# GD32A72_A74x register map
File version: 1.0
CPU: CM7 r2p1, little endian, MPU, FPU, DSP, 4 interrupt priority bits
Registers are 32-bit, read-write, reset 0x0 unless marked. A register's access mark holds for its fields unless they carry their own. Offsets are from the block's base; [hi:lo] are bit positions.

## PMU — Power management unit
Base 0x40007000
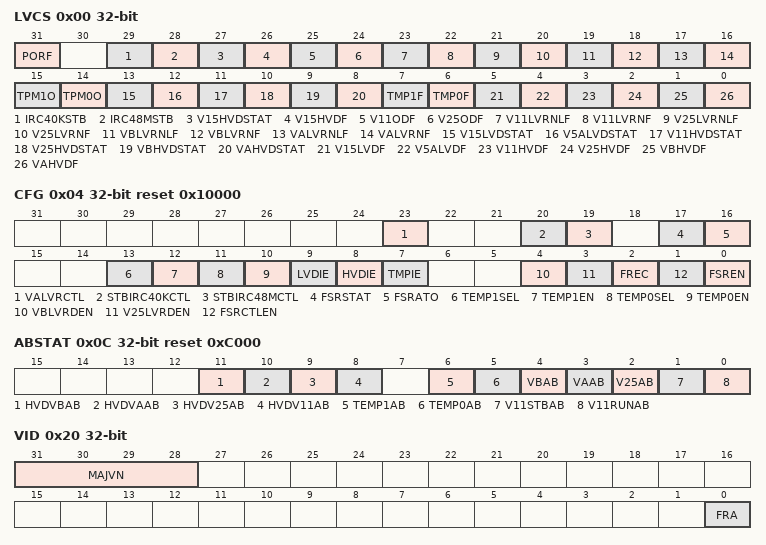
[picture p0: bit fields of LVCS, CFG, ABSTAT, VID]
0x00 LVCS access per field — Low voltage control and status register
  [31] PORF rw — POR flag
  [29] IRC40KSTB rw — irc40k stabilization status
  [28] IRC48MSTB rw — irc48m stabilization status
  [27] V15HVDSTAT ro — 1
  [26] V15HVDF rw — 1
  [25] V11ODF rw — Osc part of 1.1V domain detect flag
  [24] V25ODF rw — Osc part of 2.5V domain detect flag
  [23] V11LVRNLF rw — 1.1V domain Low voltage reset flag (NCM or LCM)
  [22] V11LVRNF rw — 1.1V domain Low voltage reset flag in NCM
  [21] V25LVRNLF rw — 2.5V domain Low voltage reset flag (NCM or LCM)
  [20] V25LVRNF rw — 2.5V domain Low voltage reset flag in NCM
  [19] VBLVRNLF rw — VDDB domain Low voltage reset flag (NCM or LCM)
  [18] VBLVRNF rw — VDDB domain Low voltage reset flag in NCM
  [17] VALVRNLF rw — VDDA domain Low voltage reset flag (NCM or LCM)
  [16] VALVRNF rw — VDDA domain Low voltage reset in NCM
  [15] TPM1O ro — Temperature monitor 1 output
  [14] TPM0O ro — Temperature monitor 0 output
  [13] V15LVDSTAT ro — 1.5V domain LVD status in NCM
  [12] V5ALVDSTAT ro — VDDA domain 5V LVD status in NCM
  [11] V11HVDSTAT ro — 1.1V domain HVD status on in NCM
  [10] V25HVDSTAT ro — 2.5V domain HVD status in NCM
  [9] VBHVDSTAT ro — VDDB domain HVD status on in NCM
  [8] VAHVDSTAT ro — VDDA domain HVD status on in NCM
  [7] TMP1F rw — Temperature monitor 1 interrupt flag for FMU
  [6] TMP0F rw — Temperature monitor 0 interrupt flag for FMU
  [5] V15LVDF rw — 1.5V domain LVD flag on in NCM
  [4] V5ALVDF rw — VDDA domain 5V LVD flag on in NCM
  [3] V11HVDF rw — 1.1V domain HVD flag on in NCM
  [2] V25HVDF rw — 2.5V domain HVD flag in NCM
  [1] VBHVDF rw — VDDB domain HVD flag in NCM
  [0] VAHVDF rw — VDDA domain HVD flag in NCM
0x04 CFG reset 0x10000 — Configuration register
  [23] VALVRCTL — control vdda lvr
  [20] STBIRC40KCTL — control whether irc40k is on in standby mode
  [19] STBIRC48MCTL — control whether irc48m is on in standby mode
  [17] FSRSTAT — Final step regulator status bit
  [16] FSRATO — Final step regulator auto turns over bit
  [13] TEMP1SEL — High temperature monitoring level selection
  [12] TEMP1EN — TEMP_M1 enable
  [11] TEMP0SEL — High temperature monitoring level selection
  [10] TEMP0EN — TEMP_M0 enable
  [9] LVDIE — Low voltage detects interrupt enable
  [8] HVDIE — High voltage detect interrupt enable
  [7] TMPIE — Temperature detect interrupt enable for FMU
  [4] VBLVRDEN — VDDB LVR detection enable bit during LCM
  [3] V25LVRDEN — 2.5V domain LVR detection enable bit during LCM
  [2] FREC — Fast recovery from LPM enable bit
  [1] FSRCTLEN — Final step regulator base control enable bit
  [0] FSREN — Final step regulator enable
0x08 ABCTL — Analog BIST control register
  [0] ABEN — Analog BIST enable signal
0x0C ABSTAT reset 0xC000 — Analog BIST status register
  [11] HVDVBAB — HVD VDDB ABIST test flag
  [10] HVDVAAB — HVD VDDA ABIST test flag
  [9] HVDV25AB — HVD V25 ABIST test flag
  [8] HVDV11AB — HVD V11 ABIST test flag
  [6] TEMP1AB — High temperature 1 ABIST
  [5] TEMP0AB — High temperature 0 ABIST
  [4] VBAB — vddb abist test status
  [3] VAAB — vdda abist test status
  [2] V25AB — 2.5V BIST test status
  [1] V11STBAB — 1.1V Standby ABIST test status
  [0] V11RUNAB — 1.1V RUN ABIST test status
0x20 VID ro — Version ID register
  [31:28] MAJVN — Major version number
  [0] FRA — Final step Regulator availability
0x24 CTLKEY — Control key register
  [15:0] CTLKEY — Control key
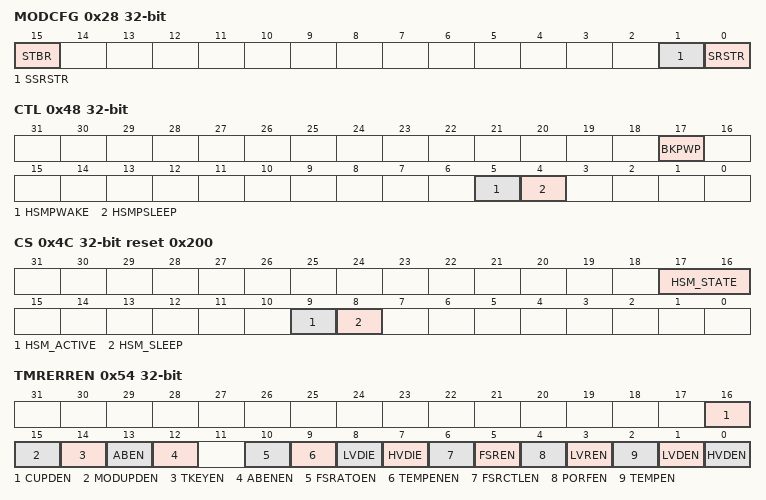
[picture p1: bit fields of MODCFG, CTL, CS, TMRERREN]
0x28 MODCFG — Mode configure register
  [15] STBR — Standby request
  [1] SSRSTR — Subsystem reset request
  [0] SRSTR — System reset request
0x2C MODUPD — Mode update register
  [0] MODUPD — Mode update
0x30 MODSTAT ro — Mode status register
  [1:0] PREMOD — Previous mode
0x34 C0BTADDR reset 0x24000000 — Core0 boot address register
  [31:0] C0BTADDR — core0 boot address
0x38 C1BTADDR reset 0x8000000 — Core1 boot address register
  [31:0] C1BTADDR — core1 boot address
0x3C MCID reset 0x8000000 — Main core ID register
  [0] MCID — main core id
0x40 CUPD — Core update register
  [0] CUPD — core update
0x48 CTL — Control register
  [17] BKPWP — Write protection for backup domain
  [5] HSMPWAKE — hsm power domain wakeup
  [4] HSMPSLEEP — hsm power domain go to power-off
0x4C CS ro reset 0x200 — Control and status register
  [17:16] HSM_STATE — HSM power state
  [9] HSM_ACTIVE — HSM power domain is in active state
  [8] HSM_SLEEP — hsm power domain is in sleep state
0x54 TMRERREN — TMR error enable register
  [16] CUPDEN — core update tmr error interrupt enable
  [15] MODUPDEN — mode update tmr error interrupt enable
  [14] TKEYEN — test key tmr error interrupt enable
  [13] ABEN — abist tmr error interrupt enable
  [12] ABENEN — abist enable interrupt enable
  [10] FSRATOEN — fsrato interrupt enable
  [9] TEMPENEN — temperature enable interrupt enable
  [8] LVDIE — lvd interrupt enable
  [7] HVDIE — hvd interrupt enable
  [6] FSRCTLEN — fsrctl interrupt enable
  [5] FSREN — fsr interrupt enable
  [4] PORFEN — porf tmr error interrupt enable
  [3] LVREN — lvr tmr error interrupt enable
  [2] TEMPEN — temperature interrupt enable
  [1] LVDEN — lvd tmr error interrupt enable
  [0] HVDEN — hvd tmr error interrupt enable
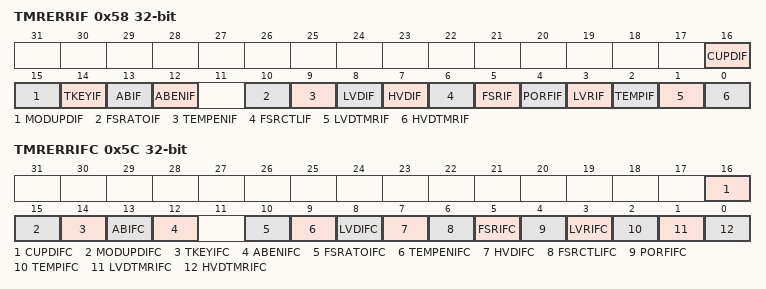
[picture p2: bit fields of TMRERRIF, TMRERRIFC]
0x58 TMRERRIF — TMR error interrupt register
  [16] CUPDIF — core update tmr error interrupt flag
  [15] MODUPDIF — mode update tmr error interrupt flag
  [14] TKEYIF — test key tmr error interrupt flag
  [13] ABIF — abist tmr error interrupt flag
  [12] ABENIF — abist enable interrupt flag
  [10] FSRATOIF — fsrato interrupt flag
  [9] TEMPENIF — temperature enable interrupt flag
  [8] LVDIF — lvd interrupt flag
  [7] HVDIF — hvd interrupt flag
  [6] FSRCTLIF — fsrctl interrupt flag
  [5] FSRIF — fsr interrupt flag
  [4] PORFIF — porf tmr error interrupt flag
  [3] LVRIF — lvr tmr error interrupt flag
  [2] TEMPIF — temperature interrupt flag
  [1] LVDTMRIF — lvd tmr error interrupt flag
  [0] HVDTMRIF — hvd tmr error interrupt flag
0x5C TMRERRIFC — TMR error interrupt clear register
  [16] CUPDIFC — core update tmr error interrupt flag clear
  [15] MODUPDIFC — mode update tmr error interrupt flag clear
  [14] TKEYIFC — test key tmr error interrupt flag clear
  [13] ABIFC — abist tmr error interrupt flag clear
  [12] ABENIFC — abist enable interrupt flag clear
  [10] FSRATOIFC — fsrato interrupt flag clear
  [9] TEMPENIFC — temperature enable interrupt flag clear
  [8] LVDIFC — lvd interrupt flag clear
  [7] HVDIFC — hvd interrupt flag clear
  [6] FSRCTLIFC — fsrctl interrupt flag clear
  [5] FSRIFC — fsr interrupt flag clear
  [4] PORFIFC — porf tmr error interrupt flag clear
  [3] LVRIFC — lvr tmr error interrupt flag clear
  [2] TEMPIFC — temperature interrupt flag clear
  [1] LVDTMRIFC — lvd tmr error interrupt flag clear
  [0] HVDTMRIFC — hvd tmr error interrupt flag clear
